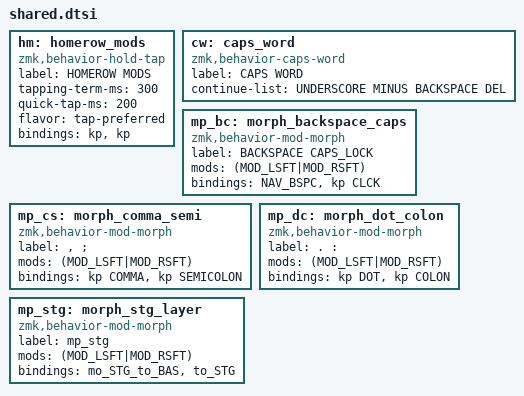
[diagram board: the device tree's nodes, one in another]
hm: homerow_mods {
    compatible = "zmk,behavior-hold-tap";
    label = "HOMEROW MODS";
    #binding-cells = <2>;
    tapping-term-ms = <300>;
    quick-tap-ms = <200>;
    flavor = "tap-preferred";
    bindings = <&kp>, <&kp>;
};

cw: caps_word {
    compatible = "zmk,behavior-caps-word";
    label = "CAPS WORD";
    #binding-cells = <0>;
    continue-list = <UNDERSCORE MINUS BACKSPACE DEL>;
};

mp_bc: morph_backspace_caps {
    compatible = "zmk,behavior-mod-morph";
    label = "BACKSPACE CAPS_LOCK";
    #binding-cells = <0>;
    mods = <(MOD_LSFT|MOD_RSFT)>;
    bindings = <NAV_BSPC>, <&kp CLCK>;
};

mp_cs: morph_comma_semi {
    compatible = "zmk,behavior-mod-morph";
    label = ", ;";
    #binding-cells = <0>;
    mods = <(MOD_LSFT|MOD_RSFT)>;
    bindings = <&kp COMMA>, <&kp SEMICOLON>;
};

mp_dc: morph_dot_colon {
    compatible = "zmk,behavior-mod-morph";
    label = ". :";
    #binding-cells = <0>;
    mods = <(MOD_LSFT|MOD_RSFT)>;
    bindings = <&kp DOT>, <&kp COLON>;
};

mp_stg: morph_stg_layer {
    compatible = "zmk,behavior-mod-morph";
    label = "mp_stg";
    #binding-cells = <0>;
    mods = <(MOD_LSFT|MOD_RSFT)>;
    bindings = <&mo_STG_to_BAS>, <&to_STG>;
};
